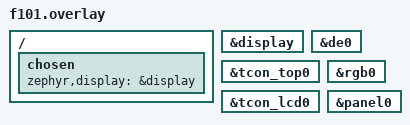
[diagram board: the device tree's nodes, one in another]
/*
 * MP4Player: the display pipeline with its panel is back on (the base overlay
 * switches it off). The SD card (smhc0), the video engine and the audio codec
 * are enabled by the board.
 */

/ {
	chosen {
		zephyr,display = &display;
	};
};


&display { status = "okay"; };
&de0 { status = "okay"; };
&tcon_top0 { status = "okay"; };
&tcon_lcd0 { status = "okay"; };
&rgb0 { status = "okay"; };
&panel0 { status = "okay"; };
